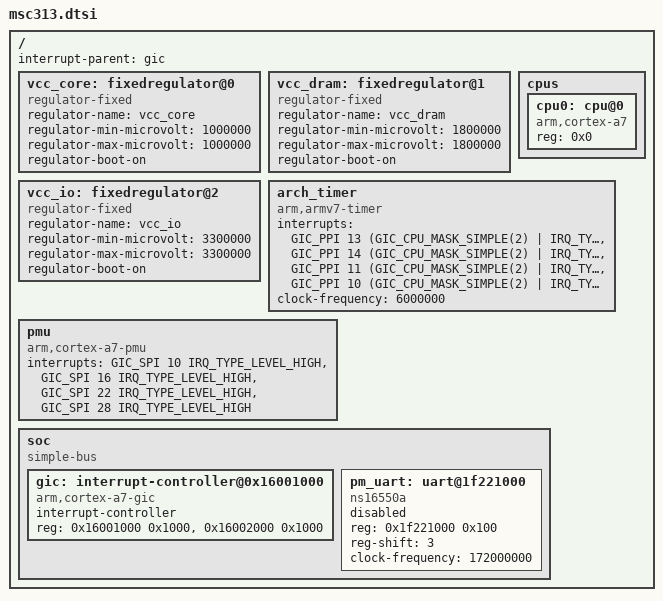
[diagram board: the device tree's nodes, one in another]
// SPDX-License-Identifier: GPL-2.0
/*
 * Copyright (c) 2019 thingy.jp.
 * Author: Daniel Palmer <daniel@thingy.jp>
 */

#include <dt-bindings/interrupt-controller/irq.h>
#include <dt-bindings/interrupt-controller/arm-gic.h>
#include <dt-bindings/gpio/gpio.h>

/ {
	#address-cells = <1>;
	#size-cells = <1>;
	interrupt-parent = <&gic>;

	vcc_core: fixedregulator@0 {
		compatible = "regulator-fixed";
		regulator-name = "vcc_core";
		regulator-min-microvolt = <1000000>;
		regulator-max-microvolt = <1000000>;
		regulator-boot-on;
	};
	
	vcc_dram: fixedregulator@1 {
		compatible = "regulator-fixed";
		regulator-name = "vcc_dram";
		regulator-min-microvolt = <1800000>;
		regulator-max-microvolt = <1800000>;
		regulator-boot-on;
	};
	
	vcc_io: fixedregulator@2 {
		compatible = "regulator-fixed";
		regulator-name = "vcc_io";
		regulator-min-microvolt = <3300000>;
		regulator-max-microvolt = <3300000>;
		regulator-boot-on;
	};

	cpus {
		#address-cells = <1>;
		#size-cells = <0>;

		cpu0: cpu@0 {
			device_type = "cpu";
			compatible = "arm,cortex-a7";
			reg = <0x0>;
		};
	};

	arch_timer {
		compatible = "arm,armv7-timer";
		interrupts = <GIC_PPI 13 (GIC_CPU_MASK_SIMPLE(2)
				| IRQ_TYPE_LEVEL_LOW)>,
			     <GIC_PPI 14 (GIC_CPU_MASK_SIMPLE(2)
				| IRQ_TYPE_LEVEL_LOW)>,
			     <GIC_PPI 11 (GIC_CPU_MASK_SIMPLE(2)
				| IRQ_TYPE_LEVEL_LOW)>,
			     <GIC_PPI 10 (GIC_CPU_MASK_SIMPLE(2)
				| IRQ_TYPE_LEVEL_LOW)>;
		clock-frequency = <6000000>;
	};

	pmu {
		compatible = "arm,cortex-a7-pmu";
		interrupts = <GIC_SPI 10 IRQ_TYPE_LEVEL_HIGH>,
			     <GIC_SPI 16 IRQ_TYPE_LEVEL_HIGH>,
			     <GIC_SPI 22 IRQ_TYPE_LEVEL_HIGH>,
			     <GIC_SPI 28 IRQ_TYPE_LEVEL_HIGH>;
	};

	soc: soc {
		compatible = "simple-bus";
		#address-cells = <1>;
		#size-cells = <1>;
		ranges;

		gic: interrupt-controller@0x16001000 {
			compatible = "arm,cortex-a7-gic";
			#interrupt-cells = <3>;
			#address-cells = <1>;
			#size-cells = <1>;
			interrupt-controller;
			reg = <0x16001000 0x1000>,
			      <0x16002000 0x1000>;
		};

		pm_uart: uart@1f221000 {
			compatible = "ns16550a";
			reg = <0x1f221000 0x100>;
			reg-shift = <3>;
			clock-frequency = <172000000>;
			status = "disabled";
		};
	};
};
